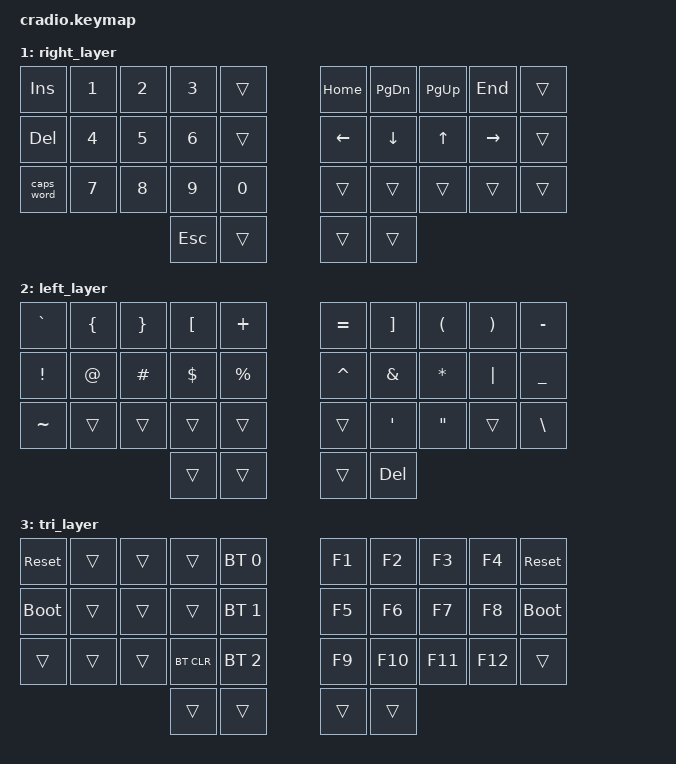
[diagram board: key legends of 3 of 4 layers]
// Copyright (c) 2022 The ZMK Contributors
// SPDX-License-Identifier: MIT

#include <behaviors.dtsi>
#include <dt-bindings/zmk/keys.h>
#include <dt-bindings/zmk/bt.h>

#define KEYS_L 0 1 2 3 4 10 11 12 13 14 20 21 22 23 24
#define KEYS_R 5 6 7 8 9 15 16 17 18 19 25 26 27 28 29
#define KEYS_T 30 31 32 33

// Home row mods macro
#define HRML(k1,k2,k3,k4) &lpht LALT k1  &lpht LGUI k2  &lpht LSHFT k3  &lpht LCTRL k4
#define HRMR(k1,k2,k3,k4) &rpht RCTRL k1  &rpht RSHFT k2  &rpht RGUI k3  &rpht RALT k4

/ {
    behaviors {
        ht: hold_tap {
            compatible = "zmk,behavior-hold-tap";
            #binding-cells = <2>;
            flavor = "tap-preferred";
            tapping-term-ms = <220>;
            quick-tap-ms = <150>;
            require-prior-idle-ms = <100>;
            bindings = <&kp>, <&kp>;
        };
        lpht: left_positional_hold_tap {
            compatible = "zmk,behavior-hold-tap";
            #binding-cells = <2>;
            flavor = "balanced";
            tapping-term-ms = <220>;
            quick-tap-ms = <175>;
            require-prior-idle-ms = <150>;
            bindings = <&kp>, <&kp>;
            hold-trigger-key-positions = <KEYS_R KEYS_T>;
            hold-trigger-on-release;
        };
        rpht: right_positional_hold_tap {
            compatible = "zmk,behavior-hold-tap";
            #binding-cells = <2>;
            flavor = "balanced";
            tapping-term-ms = <220>;
            quick-tap-ms = <175>;
            require-prior-idle-ms = <150>;
            bindings = <&kp>, <&kp>;
            hold-trigger-key-positions = <KEYS_L KEYS_T>;
            hold-trigger-on-release;
        };
    };

    conditional_layers {
        compatible = "zmk,conditional-layers";
        tri_layer {
            if-layers = <1 2>;
            then-layer = <3>;
        };
    };

    keymap {
        compatible = "zmk,keymap";
        default_layer {
            bindings = <
        //╭──────────┬──────────┬──────────┬──────────┬──────────╮   ╭──────────┬──────────┬──────────┬──────────┬──────────╮
        //│  Q       │  W       │  E       │  R       │  T       │   │  Y       │  U       │  I       │  O       │  P       │
            &kp Q      &kp W      &kp E      &kp R      &kp T          &kp Y      &kp U      &kp I      &kp O      &kp P
        //├──────────┼──────────┼──────────┼──────────┼──────────┤   ├──────────┼──────────┼──────────┼──────────┼──────────┤
        //│  A       │  S       │  D       │  F       │  G       │   │  H       │  J       │  K       │  L       │ ; :      │
            HRML(A,        S,         D,         F)     &kp G          &kp H      HRMR(J,        K,         L,         SEMI )
        //├──────────┼──────────┼──────────┼──────────┼──────────┤   ├──────────┼──────────┼──────────┼──────────┼──────────┤
        //│  Z       │  X       │  C       │  V       │  B       │   │  N       │  M       │ , <      │ . >      │ / ?      │
            &kp Z      &kp X      &kp C      &kp V      &kp B          &kp N      &kp M      &kp COMMA  &kp DOT    &kp FSLH
        //╰──────────┴──────────┴──────────┼──────────┼──────────┤   ├──────────┼──────────┼──────────┴──────────┴──────────╯
                                             &kp TAB  &lt 2 ENTER    &lt 1 SPACE  &kp BSPC
        //                                 ╰──────────┴──────────╯   ╰──────────┴──────────╯
            >;
        };

        right_layer {
            bindings = <
        //╭──────────┬──────────┬──────────┬──────────┬──────────╮   ╭──────────┬──────────┬──────────┬──────────┬──────────╮
        //│ INSERT   │  1       │  2       │  3       │          │   │ HOME     │ PAGE DN  │ PAGE UP  │ END      │          │
            &kp INS    &kp N1     &kp N2     &kp N3     &trans         &kp HOME   &kp PG_DN  &kp PG_UP  &kp END    &trans
        //├──────────┼──────────┼──────────┼──────────┼──────────┤   ├──────────┼──────────┼──────────┼──────────┼──────────┤
        //│ DELETE   │  4       │  5       │  6       │          │   │ LEFT     │ DOWN     │ UP       │ RIGHT    │          │
            &kp DEL    &kp N4     &kp N5     &kp N6     &trans         &kp LEFT   &kp DOWN   &kp UP    &kp RIGHT   &trans
        //├──────────┼──────────┼──────────┼──────────┼──────────┤   ├──────────┼──────────┼──────────┼──────────┼──────────┤
        //│ CAPS     │  7       │  8       │  9       │  0       │   │          │          │          │          │          │
           &caps_word  &kp N7     &kp N8     &kp N9     &kp N0         &trans     &trans     &trans     &trans     &trans
        //╰──────────┴──────────┴──────────┼──────────┼──────────┤   ├──────────┼──────────┼──────────┴──────────┴──────────╯
                                             &kp ESC    &trans         &trans     &trans
        //                                 ╰──────────┴──────────╯   ╰──────────┴──────────╯
            >;
        };

        left_layer {
            bindings = <
        //╭──────────┬──────────┬──────────┬──────────┬──────────╮   ╭──────────┬──────────┬──────────┬──────────┬──────────╮
        //│  `       │  {       │  }       │  [       │  +       │   │  =       │  ]       │  (       │  )       │  -       │
            &kp GRAVE  &kp LBRC   &kp RBRC   &kp LBKT   &kp PLUS       &kp EQUAL  &kp RBKT   &kp LPAR   &kp RPAR   &kp MINUS
        //├──────────┼──────────┼──────────┼──────────┼──────────┤   ├──────────┼──────────┼──────────┼──────────┼──────────┤
        //│  !       │  @       │  #       │  $       │  %       │   │  ^       │  &       │  *       │  │       │  _       │
            &kp EXCL   &kp AT     &kp HASH   &kp DLLR   &kp PRCNT      &kp CARET  &kp AMPS   &kp ASTRK  &kp PIPE   &kp UNDER
        //├──────────┼──────────┼──────────┼──────────┼──────────┤   ├──────────┼──────────┼──────────┼──────────┼──────────┤
        //│ ~        │          │          │          │          │   │          │ '        │ "        │          │  \       │
            &kp TILDE  &trans     &trans     &trans     &trans         &trans     &kp SQT    &kp DQT    &trans     &kp BSLH
        //╰──────────┴──────────┴──────────┼──────────┼──────────┤   ├──────────┼──────────┼──────────┴──────────┴──────────╯
        //                                 │          │          │   │          │  DELETE  │
                                             &trans     &trans         &trans     &kp DEL
        //                                 ╰──────────┴──────────╯   ╰──────────┴──────────╯
            >;
        };

        tri_layer {
            bindings = <
        //╭──────────┬──────────┬──────────┬──────────┬──────────╮   ╭──────────┬──────────┬──────────┬──────────┬──────────╮
        //│ RESET    │          │          │          │PROFILE 0 │   │          │          │          │          │  RESET   │
           &sys_reset  &trans     &trans     &trans    &bt BT_SEL 0    &kp F1     &kp F2     &kp F3     &kp F4    &sys_reset
        //├──────────┼──────────┼──────────┼──────────┼──────────┤   ├──────────┼──────────┼──────────┼──────────┼──────────┤
        //│BOOTLOADER│          │          │          │PROFILE 1 │   │          │          │          │          │BOOTLOADER│
          &bootloader  &trans     &trans     &trans    &bt BT_SEL 1    &kp F5     &kp F6     &kp F7     &kp F8    &bootloader
        //├──────────┼──────────┼──────────┼──────────┼──────────┤   ├──────────┼──────────┼──────────┼──────────┼──────────┤
        //│          │          │          │ CLEAR BT │PROFILE 2 │   │          │          │          │          │          │
            &trans     &trans     &trans    &bt BT_CLR &bt BT_SEL 2    &kp F9     &kp F10    &kp F11    &kp F12    &trans
        //╰──────────┴──────────┴──────────┼──────────┼──────────┤   ├──────────┼──────────┼──────────┴──────────┴──────────╯
                                             &trans     &trans         &trans     &trans
        //                                 ╰──────────┴──────────╯   ╰──────────┴──────────╯
            >;
        };
    };
};
